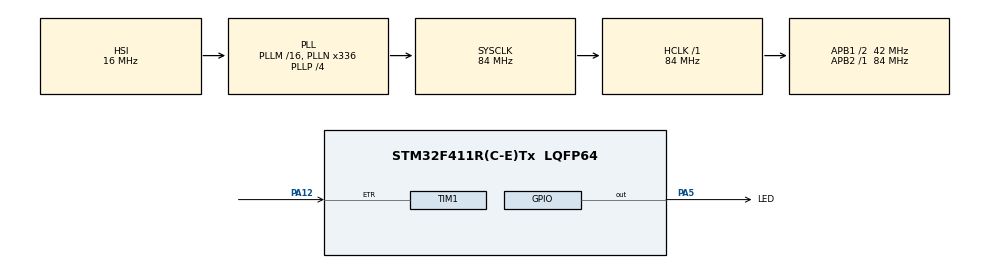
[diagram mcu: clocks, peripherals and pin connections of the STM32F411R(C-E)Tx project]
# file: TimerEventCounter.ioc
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Mcu.Family=STM32F4
Mcu.Name=STM32F411R(C-E)Tx
Mcu.Package=LQFP64
NVIC.PriorityGroup=NVIC_PRIORITYGROUP_0
NVIC.TIM1_UP_TIM10_IRQn=true\:0\:0\:false\:false\:true\:true\:true
PA12.Signal=S_TIM1_ETR
PA5.GPIO_Label=LED
PA5.Signal=GPIO_Output
ProjectManager.HeapSize=0x200
ProjectManager.StackSize=0x400
ProjectManager.TargetToolchain=STM32CubeIDE
RCC.48MHZClocksFreq_Value=84000000
RCC.AHBFreq_Value=84000000
RCC.APB1CLKDivider=RCC_HCLK_DIV2
RCC.APB1Freq_Value=42000000
RCC.APB1TimFreq_Value=84000000
RCC.APB2Freq_Value=84000000
RCC.APB2TimFreq_Value=84000000
RCC.CortexFreq_Value=84000000
RCC.FLatency-AdvancedSettings=FLASH_LATENCY_2
RCC.HCLKFreq_Value=84000000
RCC.HSE_VALUE=8000000
RCC.HSI_VALUE=16000000
RCC.PLLN=336
RCC.PLLP=RCC_PLLP_DIV4
RCC.SYSCLKFreq_VALUE=84000000
RCC.SYSCLKSource=RCC_SYSCLKSOURCE_PLLCLK
RCC.VCOOutputFreq_Value=336000000
SH.S_TIM1_ETR.0=TIM1_ETR,ClockSourceETR_Mode2
TIM1.Period=5
board=NUCLEO-F411RE

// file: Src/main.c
/* USER CODE BEGIN Header */
/**
  ******************************************************************************
  * @file           : main.c
  * @brief          : Main program body
  ******************************************************************************
  * @attention
  *
  * <h2><center>&copy; Copyright (c) 2020 STMicroelectronics.
  * All rights reserved.</center></h2>
  *
  * This software component is licensed by ST under BSD 3-Clause license,
  * the "License"; You may not use this file except in compliance with the
  * License. You may obtain a copy of the License at:
  *                        opensource.org/licenses/BSD-3-Clause
  *
  ******************************************************************************
  */
/* USER CODE END Header */

#include "main.h"

TIM_HandleTypeDef htim1;

void SystemClock_Config(void);
static void MX_GPIO_Init(void);
static void MX_TIM1_Init(void);

/* USER CODE BEGIN 0 */
void HAL_TIM_PeriodElapsedCallback(TIM_HandleTypeDef *htim)
{
	HAL_GPIO_TogglePin(LED_Pin, LED_GPIO_Port);
}
/* USER CODE END 0 */

int main(void)
{

  /* MCU Configuration--------------------------------------------------------*/

  /* Reset of all peripherals, Initializes the Flash interface and the Systick. */
  HAL_Init();

  /* Configure the system clock */
  SystemClock_Config();

  /* Initialize all configured peripherals */
  MX_GPIO_Init();
  MX_TIM1_Init();
  /* USER CODE BEGIN 2 */
  HAL_TIM_Base_Start_IT(&htim1);
  /* USER CODE END 2 */

  /* Infinite loop */
  while (1)
  {

  }
}

void SystemClock_Config(void)
{
  RCC_OscInitTypeDef RCC_OscInitStruct = {0};
  RCC_ClkInitTypeDef RCC_ClkInitStruct = {0};

  /** Configure the main internal regulator output voltage
  */
  __HAL_RCC_PWR_CLK_ENABLE();
  __HAL_PWR_VOLTAGESCALING_CONFIG(PWR_REGULATOR_VOLTAGE_SCALE1);
  /** Initializes the CPU, AHB and APB busses clocks
  */
  RCC_OscInitStruct.OscillatorType = RCC_OSCILLATORTYPE_HSI;
  RCC_OscInitStruct.HSIState = RCC_HSI_ON;
  RCC_OscInitStruct.HSICalibrationValue = RCC_HSICALIBRATION_DEFAULT;
  RCC_OscInitStruct.PLL.PLLState = RCC_PLL_ON;
  RCC_OscInitStruct.PLL.PLLSource = RCC_PLLSOURCE_HSI;
  RCC_OscInitStruct.PLL.PLLM = 16;
  RCC_OscInitStruct.PLL.PLLN = 336;
  RCC_OscInitStruct.PLL.PLLP = RCC_PLLP_DIV4;
  RCC_OscInitStruct.PLL.PLLQ = 4;
  if (HAL_RCC_OscConfig(&RCC_OscInitStruct) != HAL_OK)
  {
    Error_Handler();
  }
  /** Initializes the CPU, AHB and APB busses clocks
  */
  RCC_ClkInitStruct.ClockType = RCC_CLOCKTYPE_HCLK|RCC_CLOCKTYPE_SYSCLK
                              |RCC_CLOCKTYPE_PCLK1|RCC_CLOCKTYPE_PCLK2;
  RCC_ClkInitStruct.SYSCLKSource = RCC_SYSCLKSOURCE_PLLCLK;
  RCC_ClkInitStruct.AHBCLKDivider = RCC_SYSCLK_DIV1;
  RCC_ClkInitStruct.APB1CLKDivider = RCC_HCLK_DIV2;
  RCC_ClkInitStruct.APB2CLKDivider = RCC_HCLK_DIV1;

  if (HAL_RCC_ClockConfig(&RCC_ClkInitStruct, FLASH_LATENCY_2) != HAL_OK)
  {
    Error_Handler();
  }
}

static void MX_TIM1_Init(void)
{

  TIM_ClockConfigTypeDef sClockSourceConfig = {0};
  TIM_MasterConfigTypeDef sMasterConfig = {0};

  htim1.Instance = TIM1;
  htim1.Init.Prescaler = 0;
  htim1.Init.CounterMode = TIM_COUNTERMODE_UP;
  htim1.Init.Period = 5;
  htim1.Init.ClockDivision = TIM_CLOCKDIVISION_DIV1;
  htim1.Init.RepetitionCounter = 0;
  htim1.Init.AutoReloadPreload = TIM_AUTORELOAD_PRELOAD_DISABLE;
  if (HAL_TIM_Base_Init(&htim1) != HAL_OK)
  {
    Error_Handler();
  }
  sClockSourceConfig.ClockSource = TIM_CLOCKSOURCE_ETRMODE2;
  sClockSourceConfig.ClockPolarity = TIM_CLOCKPOLARITY_NONINVERTED;
  sClockSourceConfig.ClockPrescaler = TIM_CLOCKPRESCALER_DIV1;
  sClockSourceConfig.ClockFilter = 0;
  if (HAL_TIM_ConfigClockSource(&htim1, &sClockSourceConfig) != HAL_OK)
  {
    Error_Handler();
  }
  sMasterConfig.MasterOutputTrigger = TIM_TRGO_RESET;
  sMasterConfig.MasterSlaveMode = TIM_MASTERSLAVEMODE_DISABLE;
  if (HAL_TIMEx_MasterConfigSynchronization(&htim1, &sMasterConfig) != HAL_OK)
  {
    Error_Handler();
  }

}

static void MX_GPIO_Init(void)
{
  GPIO_InitTypeDef GPIO_InitStruct = {0};

  /* GPIO Ports Clock Enable */
  __HAL_RCC_GPIOA_CLK_ENABLE();

  /*Configure GPIO pin Output Level */
  HAL_GPIO_WritePin(LED_GPIO_Port, LED_Pin, GPIO_PIN_RESET);

  /*Configure GPIO pin : LED_Pin */
  GPIO_InitStruct.Pin = LED_Pin;
  GPIO_InitStruct.Mode = GPIO_MODE_OUTPUT_PP;
  GPIO_InitStruct.Pull = GPIO_NOPULL;
  GPIO_InitStruct.Speed = GPIO_SPEED_FREQ_LOW;
  HAL_GPIO_Init(LED_GPIO_Port, &GPIO_InitStruct);

}

void Error_Handler(void)
{
}

/************************ (C) COPYRIGHT STMicroelectronics *****END OF FILE****/
